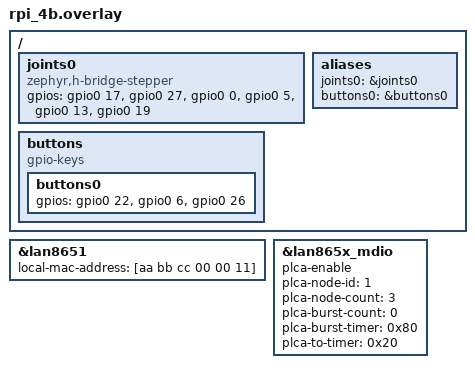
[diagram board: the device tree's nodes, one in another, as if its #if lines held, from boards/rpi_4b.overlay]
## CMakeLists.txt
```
# SPDX-License-Identifier: Apache-2.0

cmake_minimum_required(VERSION 3.20.0)
find_package(Zephyr REQUIRED HINTS $ENV{ZEPHYR_BASE})
project(robot_arm_slave)

add_subdirectory(tickle)  # TODO: Include tickle as external module

target_include_directories(app PRIVATE ${TICKLE_INCLUDE_DIRS})
target_sources(app PRIVATE src/main.c src/Command.c ${TICKLE_SOURCES})
```

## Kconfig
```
source "Kconfig.zephyr"

config ROBOTARM_SLAVE_IS_FIRST
	bool "Robotarm slave number"
	default y
	
```

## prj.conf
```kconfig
# TODO: Enable this when tickle is included as an external module
#CONFIG_TICKLE=y
CONFIG_POSIX_NETWORKING=y
CONFIG_POSIX_API=y

CONFIG_NET_IPV4=y
CONFIG_NET_DHCPV4=n
CONFIG_NET_UDP=y
CONFIG_NET_SOCKETS=y

CONFIG_NET_CONFIG_SETTINGS=y
CONFIG_NET_CONFIG_NEED_IPV4=y
CONFIG_NET_CONFIG_MY_IPV4_NETMASK="255.255.255.0"

CONFIG_MAIN_STACK_SIZE=16384

CONFIG_NET_CONTEXT_RCVTIMEO=y

# Leave these as default
CONFIG_ROBOTARM_SLAVE_IS_FIRST=y
CONFIG_NET_CONFIG_MY_IPV4_ADDR="192.168.10.2"
```

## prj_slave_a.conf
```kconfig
CONFIG_ROBOTARM_SLAVE_IS_FIRST=y
CONFIG_NET_CONFIG_MY_IPV4_ADDR="192.168.10.2"
```

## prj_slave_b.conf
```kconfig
CONFIG_ROBOTARM_SLAVE_IS_FIRST=n
CONFIG_NET_CONFIG_MY_IPV4_ADDR="192.168.10.3"
```

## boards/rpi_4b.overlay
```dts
/ {
	joints0: joints0 {
		compatible = "zephyr,h-bridge-stepper";

		gpios = <&gpio0 17 GPIO_ACTIVE_HIGH>,
				<&gpio0 27 GPIO_ACTIVE_HIGH>,
				<&gpio0 0 GPIO_ACTIVE_HIGH>,
				<&gpio0 5 GPIO_ACTIVE_HIGH>,
				<&gpio0 13 GPIO_ACTIVE_HIGH>,
				<&gpio0 19 GPIO_ACTIVE_HIGH>;
	};

	buttons: buttons {
		compatible = "gpio-keys";

		buttons0: buttons0 {
			gpios = <&gpio0 22 GPIO_ACTIVE_HIGH>,
					<&gpio0 6 GPIO_ACTIVE_HIGH>,
					<&gpio0 26 GPIO_ACTIVE_HIGH>;
		};
	};

	aliases {
		joints0 = &joints0;
		buttons0 = &buttons0;
	};
};

&lan8651 {
#if defined(CONFIG_ROBOTARM_SLAVE_IS_FIRST)
	local-mac-address = [aa bb cc 00 00 11];
#else
	local-mac-address = [aa bb cc 00 00 22];
#endif
};

&lan865x_mdio {
	plca-enable;
#if defined(CONFIG_ROBOTARM_SLAVE_IS_FIRST)
	plca-node-id = <1>;
#else
	plca-node-id = <2>;
#endif
	plca-node-count = <3>;
	plca-burst-count = <0>;
	plca-burst-timer = <0x80>;
	plca-to-timer = <0x20>;
};
```

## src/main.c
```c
#include <stdio.h>
#include <zephyr/kernel.h>

#include <zephyr/net/ethernet.h>
#include <zephyr/net/net_if.h>
#include <zephyr/net/net_mgmt.h>

#include <zephyr/drivers/gpio.h>

#include <tickle/tickle.h>
#include "Command.h"

#define PPR 16000

#define PULSE_COUNT 20
#define JOINT_COUNT 3

#define JOINTS_NODE DT_ALIAS(joints0)
#define BUTTONS_NODE DT_ALIAS(buttons0)

static inline bool is_my_joint(uint8_t joint) {
#ifdef CONFIG_ROBOTARM_SLAVE_IS_FIRST
    return joint == 1 || joint == 3 || joint == 5;
#else
    return joint == 2 || joint == 4 || joint == 6;
#endif /* CONFIG_ROBOTARM_SLAVE_IS_FIRST */
}

enum JOINT_DIRECTION {
    LEFT,
    RIGHT,
};

static const struct gpio_dt_spec joint1_pulse = GPIO_DT_SPEC_GET_BY_IDX(JOINTS_NODE, gpios, 0);
static const struct gpio_dt_spec joint1_direction = GPIO_DT_SPEC_GET_BY_IDX(JOINTS_NODE, gpios, 1);
static const struct gpio_dt_spec joint1_limit_button = GPIO_DT_SPEC_GET_BY_IDX(BUTTONS_NODE, gpios, 0);
static const struct gpio_dt_spec joint2_pulse = GPIO_DT_SPEC_GET_BY_IDX(JOINTS_NODE, gpios, 2);
static const struct gpio_dt_spec joint2_direction = GPIO_DT_SPEC_GET_BY_IDX(JOINTS_NODE, gpios, 3);
static const struct gpio_dt_spec joint2_limit_button = GPIO_DT_SPEC_GET_BY_IDX(BUTTONS_NODE, gpios, 1);
static const struct gpio_dt_spec joint3_pulse = GPIO_DT_SPEC_GET_BY_IDX(JOINTS_NODE, gpios, 4);
static const struct gpio_dt_spec joint3_direction = GPIO_DT_SPEC_GET_BY_IDX(JOINTS_NODE, gpios, 5);
static const struct gpio_dt_spec joint3_limit_button = GPIO_DT_SPEC_GET_BY_IDX(BUTTONS_NODE, gpios, 2);

static const struct gpio_dt_spec dummy_dt_spec = {
    .port = NULL,
    .pin = 0,
    .dt_flags = 0,
};

static const struct gpio_dt_spec pulse_pins[] = {
    dummy_dt_spec,
#ifdef CONFIG_ROBOTARM_SLAVE_IS_FIRST
    joint1_pulse,
    dummy_dt_spec,
    joint2_pulse,
    dummy_dt_spec,
    joint3_pulse,
    dummy_dt_spec,
#else
    dummy_dt_spec,
    joint1_pulse,
    dummy_dt_spec,
    joint2_pulse,
    dummy_dt_spec,
    joint3_pulse,
#endif /* CONFIG_ROBOTARM_SLAVE_IS_FIRST */
};

static const struct gpio_dt_spec direction_pins[] = {
    dummy_dt_spec,
#ifdef CONFIG_ROBOTARM_SLAVE_IS_FIRST
    joint1_direction,
    dummy_dt_spec,
    joint2_direction,
    dummy_dt_spec,
    joint3_direction,
    dummy_dt_spec,
#else
    dummy_dt_spec,
    joint1_direction,
    dummy_dt_spec,
    joint2_direction,
    dummy_dt_spec,
    joint3_direction,
#endif /* CONFIG_ROBOTARM_SLAVE_IS_FIRST */
};

static const struct gpio_dt_spec limit_buttons[] = {
    dummy_dt_spec,
#ifndef CONFIG_ROBOTARM_SLAVE_IS_FIRST
    dummy_dt_spec,
    dummy_dt_spec,
    dummy_dt_spec,
#endif /* CONFIG_ROBOTARM_SLAVE_IS_FIRST */
    joint1_limit_button,
    joint2_limit_button,
    joint3_limit_button,
};

static int32_t current_angles[7] = {
    0,
};

static bool check_joint_limit_button(uint8_t joint) {
    if (!is_my_joint(joint)) {
        printk("Error: Joint %d is out of range\n", joint);
        return false;
    }

    return gpio_pin_get_dt(&limit_buttons[joint]) != 0;
}

static void move_joint_step(uint8_t joint, enum JOINT_DIRECTION direction) {
    // TODO: Check limit button
    switch (direction) {
        case LEFT:
            gpio_pin_set_dt(&direction_pins[joint], 0);
            break;
        case RIGHT:
            gpio_pin_set_dt(&direction_pins[joint], 1);
            break;
    }

    for (int i = 0; i < PULSE_COUNT; i++) {
        gpio_pin_set_dt(&pulse_pins[joint], 0);
        k_busy_wait(100);
        gpio_pin_set_dt(&pulse_pins[joint], 1);
        k_busy_wait((joint == 1 || joint == 3) ? 250 : 500);
    }
}

static void move_joint(uint8_t joint, int32_t angle) {
    int32_t angle_diff = angle - current_angles[joint];
    int32_t steps = (angle_diff * PPR) / 360;
    if (steps < 0) {
        steps *= -1;
    }
    for (int32_t i = 0; i < steps; i++) {
        move_joint_step(joint, angle_diff > 0 ? RIGHT : LEFT);
    }
    current_angles[joint] = angle;
}

static void do_calibration(void) {
    printk("Starting calibration\n");

#ifdef CONFIG_ROBOTARM_SLAVE_IS_FIRST
    while (true) {
        move_joint_step(1, LEFT);
        if (check_joint_limit_button(1)) {
            break;
        }
    }

    while (true) {
        move_joint_step(3, RIGHT);
        if (check_joint_limit_button(3)) {
            break;
        }
    }

    for (int i = 0; i < 50; i++) {
        move_joint_step(3, LEFT);
    }
#else
    while (true) {
        move_joint_step(2, LEFT);
        if (check_joint_limit_button(2)) {
            break;
        }
    }

    while (true) {
        move_joint_step(4, LEFT);
        if (check_joint_limit_button(4)) {
            break;
        }
    }
#endif /* CONFIG_ROBOTARM_SLAVE_IS_FIRST */
    printk("Calibration finished\n");
}

static void command_callback(struct tt_Subscriber* sub, uint64_t timestamp, uint16_t seq_no, struct CommandData* data) {
    printk("Received command: %u, %d\n", data->joint, data->angle);
    if (is_my_joint(data->joint)) {
        move_joint(data->joint, data->angle);
    }
}

int main(void)
{
    printk("Slave Node Started\n");

    _tt_CONFIG.broadcast = "192.168.10.255";

    do_calibration();

    struct tt_Node node;
    int32_t ret = tt_Node_create(&node);
    if (ret != 0) {
        printk("Failed to create node: %d\n", ret);
        return ret;
    }

    printk("Slave Node Created, Node ID: %d\n", node.id);

    struct tt_Subscriber sub;

    ret = tt_Node_create_subscriber(&node, &sub, &CommandTopic, "command_topic", (tt_SUBSCRIBER_CALLBACK)command_callback);
    if (ret != 0) {
        printk("Failed to create subscriber: %d\n", ret);
        return ret;
    }

    tt_Node_poll(&node);

    tt_Node_destroy(&node);

	return 0;
}
```

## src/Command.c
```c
#include "Command.h"

#include <tickle/hal.h>
#include <zephyr/sys/byteorder.h>

struct tt_Topic CommandTopic = {
    .name = "CommandTopic",
    .data_size = sizeof(struct CommandData),
    .data_encode_size = (tt_DATA_ENCODE_SIZE)CommandData_encode_size,
    .data_encode = (tt_DATA_ENCODE)CommandData_encode,
    .data_decode = (tt_DATA_DECODE)CommandData_decode,
    .data_free = (tt_DATA_FREE)CommandData_free,
};

int32_t CommandData_encode_size(struct CommandData* data) {
    return sizeof(uint8_t) + sizeof(int32_t);
}

int32_t CommandData_encode(struct CommandData* data, uint8_t* payload, const int32_t len) {
    int32_t encoded = 0;

    if (encoded + sizeof(uint8_t) > len) {
        return -1;
    }

    *(uint8_t*)payload = data->joint;

    encoded += sizeof(uint8_t);
    payload += sizeof(uint8_t);

    if (encoded + sizeof(int32_t) > len) {
        return -1;
    }

    *(int32_t*)payload = sys_cpu_to_be32(data->angle);
    payload += sizeof(int32_t);
    encoded += sizeof(int32_t);

    return encoded;
}

int32_t CommandData_decode(struct CommandData* data, const uint8_t* payload, const int32_t len, bool is_native_endian) {
    int32_t decoded = 0;

    if (decoded + sizeof(uint8_t) > len) {
        return -1;
    }

    data->joint = *(uint8_t*)payload;

    decoded += sizeof(uint8_t);
    payload += sizeof(uint8_t);

    if (decoded + sizeof(int32_t) > len) {
        return -1;
    }

    data->angle = sys_be32_to_cpu(*(int32_t*)payload);

    decoded += sizeof(int32_t);
    payload += sizeof(int32_t);

    return decoded;
}

void CommandData_free(struct CommandData* data) {
    // Do nothing
}
```

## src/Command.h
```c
#pragma once

#include <tickle/tickle.h>

struct CommandData {
    uint8_t joint;
    int32_t angle;
};

extern struct tt_Topic CommandTopic;

int32_t CommandData_encode_size(struct CommandData* request);
int32_t CommandData_encode(struct CommandData* request, uint8_t* payload, const int32_t len);
int32_t CommandData_decode(struct CommandData* request, const uint8_t* payload, const int32_t len, bool is_native_endian);
void CommandData_free(struct CommandData* request);
```

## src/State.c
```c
#include "State.h"

#include <tickle/hal.h>
#include <zephyr/sys/byteorder.h>

struct tt_Topic StateTopic = {
    .name = "StateTopic",
    .data_size = sizeof(struct StateData),
    .data_encode_size = (tt_DATA_ENCODE_SIZE)StateData_encode_size,
    .data_encode = (tt_DATA_ENCODE)StateData_encode,
    .data_decode = (tt_DATA_DECODE)StateData_decode,
    .data_free = (tt_DATA_FREE)StateData_free,
};

int32_t StateData_encode_size(struct StateData* data) {
    return sizeof(uint8_t) + sizeof(int32_t);
}

int32_t StateData_encode(struct StateData* data, uint8_t* payload, const int32_t len) {
    int32_t encoded = 0;

    if (encoded + sizeof(uint8_t) > len) {
        return -1;
    }

    *(uint8_t*)payload = data->id;

    encoded += sizeof(uint8_t);
    payload += sizeof(uint8_t);

    if (encoded + sizeof(int32_t) > len) {
        return -1;
    }

    *(int32_t*)payload = sys_cpu_to_be32(data->status);
    payload += sizeof(int32_t);
    encoded += sizeof(int32_t);

    return encoded;
}

int32_t StateData_decode(struct StateData* data, const uint8_t* payload, const int32_t len, bool is_native_endian) {
    int32_t decoded = 0;

    if (decoded + sizeof(uint8_t) > len) {
        return -1;
    }

    data->id = *(uint8_t*)payload;

    decoded += sizeof(uint8_t);
    payload += sizeof(uint8_t);

    if (decoded + sizeof(int32_t) > len) {
        return -1;
    }

    data->status = sys_be32_to_cpu(*(int32_t*)payload);

    decoded += sizeof(int32_t);
    payload += sizeof(int32_t);

    return decoded;
}

void StateData_free(struct StateData* data) {
    // Do nothing
}
```
